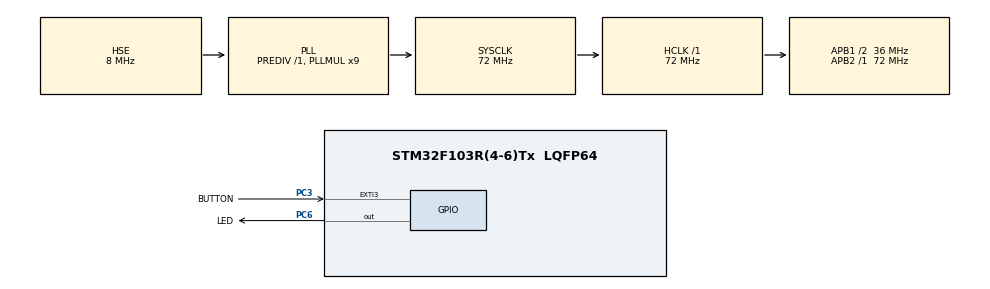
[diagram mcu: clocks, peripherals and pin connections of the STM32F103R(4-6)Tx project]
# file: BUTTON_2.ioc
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Mcu.Family=STM32F1
RCC.PLLSourceVirtual=RCC_PLLSOURCE_HSE
PD1-OSC_OUT.Mode=HSE-External-Oscillator
PC3.GPIO_ModeDefaultEXTI=GPIO_MODE_IT_RISING_FALLING
PC6.Signal=GPIO_Output
NVIC.EXTI3_IRQn=true\:0\:0\:false\:false\:true\:true\:true
PC6.GPIO_Label=LED
PD0-OSC_IN.Signal=RCC_OSC_IN
RCC.APB1CLKDivider=RCC_HCLK_DIV2
VP_SYS_VS_ND.Mode=No_Debug
RCC.SYSCLKSource=RCC_SYSCLKSOURCE_PLLCLK
ProjectManager.StackSize=0x400
PD1-OSC_OUT.Signal=RCC_OSC_OUT
ProjectManager.TargetToolchain=MDK-ARM V5
RCC.HCLKFreq_Value=72000000
RCC.APB2TimFreq_Value=72000000
PC3.Signal=GPXTI3
RCC.USBFreq_Value=72000000
RCC.AHBFreq_Value=72000000
PD0-OSC_IN.Mode=HSE-External-Oscillator
PC6.PinState=GPIO_PIN_RESET
board=custom
RCC.PLLMUL=RCC_PLL_MUL9
RCC.APB2Freq_Value=72000000
Mcu.Name=STM32F103R(4-6)Tx
RCC.SYSCLKFreq_VALUE=72000000
Mcu.Package=LQFP64
ProjectManager.HeapSize=0x200
PC6.GPIO_PuPd=GPIO_NOPULL
NVIC.PriorityGroup=NVIC_PRIORITYGROUP_4
RCC.APB1TimFreq_Value=72000000
PC3.GPIO_Label=BUTTON
RCC.APB1Freq_Value=36000000
PC6.GPIO_Speed=GPIO_SPEED_FREQ_LOW
PC3.GPIO_PuPd=GPIO_PULLUP

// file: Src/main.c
/* USER CODE BEGIN Header */
/**
  ******************************************************************************
  * @file           : main.c
  * @brief          : Main program body
  ******************************************************************************
  * @attention
  *
  * <h2><center>&copy; Copyright (c) 2020 STMicroelectronics.
  * All rights reserved.</center></h2>
  *
  * This software component is licensed by ST under BSD 3-Clause license,
  * the "License"; You may not use this file except in compliance with the
  * License. You may obtain a copy of the License at:
  *                        opensource.org/licenses/BSD-3-Clause
  *
  ******************************************************************************
  */
/* USER CODE END Header */
#include "main.h"
#include "gpio.h"

void SystemClock_Config(void);

/* USER CODE BEGIN 0 */
uint8_t exit_flag = 0;  // 用于防抖的标志位
uint8_t up_or_down = 0;  // 上升沿为1、下降沿为0

void HAL_GPIO_EXTI_Callback(uint16_t GPIO_Pin)
{
	// 防误触双层判断
	if (GPIO_Pin == BUTTON_Pin)
	{
		if (exit_flag == 0)
		{
			exit_flag = 1;
			up_or_down = HAL_GPIO_ReadPin(BUTTON_GPIO_Port, BUTTON_Pin);
		}
	}
}
/* USER CODE END 0 */

int main(void)
{

  /* MCU Configuration--------------------------------------------------------*/

  /* Reset of all peripherals, Initializes the Flash interface and the Systick. */
  HAL_Init();

  /* Configure the system clock */
  SystemClock_Config();

  /* Initialize all configured peripherals */
  MX_GPIO_Init();
  /* USER CODE BEGIN 2 */
	HAL_GPIO_WritePin(GPIOC, LED_Pin, GPIO_PIN_SET);  // 外部电源，高电平关闭LED
  /* USER CODE END 2 */

  /* Infinite loop */
  while (1)
  {

    /* USER CODE BEGIN 3 */
		if (exit_flag == 1)
		{
			exit_flag = 2;
			// 防抖动
			if (up_or_down == GPIO_PIN_SET)
			{
				HAL_Delay(20);
				if (HAL_GPIO_ReadPin(BUTTON_GPIO_Port, BUTTON_Pin) == up_or_down)
				{
					HAL_GPIO_WritePin(GPIOC, LED_Pin, GPIO_PIN_SET);
					exit_flag = 0;
				}
			}
			else if (up_or_down == GPIO_PIN_RESET)
			{
				HAL_Delay(20);
				if (HAL_GPIO_ReadPin(BUTTON_GPIO_Port, BUTTON_Pin) == up_or_down)
				{
					HAL_GPIO_WritePin(GPIOC, LED_Pin, GPIO_PIN_RESET);
					exit_flag = 0;
				}
			}
		}
  }
  /* USER CODE END 3 */
}

void SystemClock_Config(void)
{
  RCC_OscInitTypeDef RCC_OscInitStruct = {0};
  RCC_ClkInitTypeDef RCC_ClkInitStruct = {0};

  /** Initializes the RCC Oscillators according to the specified parameters
  * in the RCC_OscInitTypeDef structure.
  */
  RCC_OscInitStruct.OscillatorType = RCC_OSCILLATORTYPE_HSE;
  RCC_OscInitStruct.HSEState = RCC_HSE_ON;
  RCC_OscInitStruct.HSEPredivValue = RCC_HSE_PREDIV_DIV1;
  RCC_OscInitStruct.HSIState = RCC_HSI_ON;
  RCC_OscInitStruct.PLL.PLLState = RCC_PLL_ON;
  RCC_OscInitStruct.PLL.PLLSource = RCC_PLLSOURCE_HSE;
  RCC_OscInitStruct.PLL.PLLMUL = RCC_PLL_MUL9;
  if (HAL_RCC_OscConfig(&RCC_OscInitStruct) != HAL_OK)
  {
    Error_Handler();
  }
  /** Initializes the CPU, AHB and APB buses clocks
  */
  RCC_ClkInitStruct.ClockType = RCC_CLOCKTYPE_HCLK|RCC_CLOCKTYPE_SYSCLK
                              |RCC_CLOCKTYPE_PCLK1|RCC_CLOCKTYPE_PCLK2;
  RCC_ClkInitStruct.SYSCLKSource = RCC_SYSCLKSOURCE_PLLCLK;
  RCC_ClkInitStruct.AHBCLKDivider = RCC_SYSCLK_DIV1;
  RCC_ClkInitStruct.APB1CLKDivider = RCC_HCLK_DIV2;
  RCC_ClkInitStruct.APB2CLKDivider = RCC_HCLK_DIV1;

  if (HAL_RCC_ClockConfig(&RCC_ClkInitStruct, FLASH_LATENCY_2) != HAL_OK)
  {
    Error_Handler();
  }
}

void Error_Handler(void)
{
}

/************************ (C) COPYRIGHT STMicroelectronics *****END OF FILE****/
